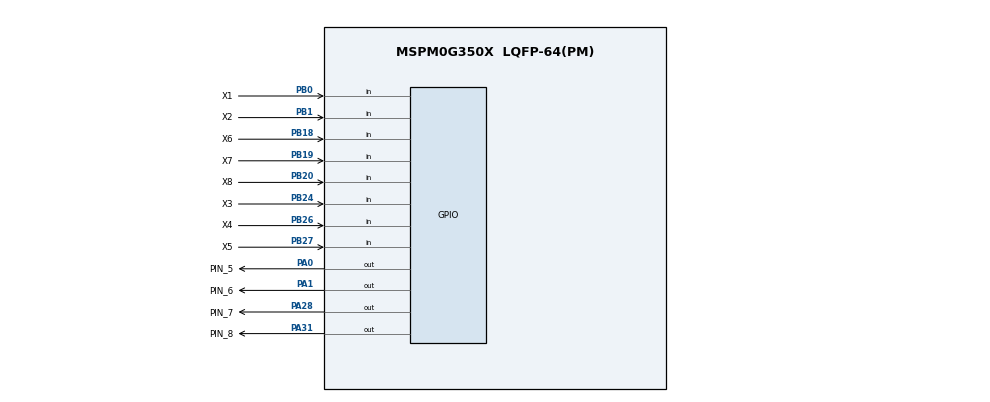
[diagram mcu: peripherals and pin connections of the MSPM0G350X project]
/**
 * @cliArgs --device "MSPM0G350X" --part "Default" --package "LQFP-64(PM)" --product "mspm0_sdk@2.10.00.04"
 * @versions {"tool":"1.26.2+4477"}
 */

/**
 * Import the modules used in this configuration.
 */
const GPIO   = scripting.addModule("/ti/driverlib/GPIO", {}, false);
const GPIO1  = GPIO.addInstance();
const GPIO2  = GPIO.addInstance();
const SYSCTL = scripting.addModule("/ti/driverlib/SYSCTL");

/**
 * Write custom configuration values to the imported modules.
 */
GPIO1.$name                              = "IR_SENSOR";
GPIO1.associatedPins.create(8);
GPIO1.associatedPins[0].$name            = "X1";
GPIO1.associatedPins[0].direction        = "INPUT";
GPIO1.associatedPins[0].internalResistor = "PULL_UP";
GPIO1.associatedPins[0].pin.$assign      = "PB0";
GPIO1.associatedPins[1].$name            = "X2";
GPIO1.associatedPins[1].direction        = "INPUT";
GPIO1.associatedPins[1].internalResistor = "PULL_UP";
GPIO1.associatedPins[1].pin.$assign      = "PB1";
GPIO1.associatedPins[2].$name            = "X3";
GPIO1.associatedPins[2].direction        = "INPUT";
GPIO1.associatedPins[2].internalResistor = "PULL_UP";
GPIO1.associatedPins[2].pin.$assign      = "PB24";
GPIO1.associatedPins[3].$name            = "X4";
GPIO1.associatedPins[3].direction        = "INPUT";
GPIO1.associatedPins[3].internalResistor = "PULL_UP";
GPIO1.associatedPins[3].pin.$assign      = "PB26";
GPIO1.associatedPins[4].$name            = "X5";
GPIO1.associatedPins[4].direction        = "INPUT";
GPIO1.associatedPins[4].internalResistor = "PULL_UP";
GPIO1.associatedPins[4].pin.$assign      = "PB27";
GPIO1.associatedPins[5].$name            = "X6";
GPIO1.associatedPins[5].direction        = "INPUT";
GPIO1.associatedPins[5].internalResistor = "PULL_UP";
GPIO1.associatedPins[5].pin.$assign      = "PB18";
GPIO1.associatedPins[6].$name            = "X7";
GPIO1.associatedPins[6].direction        = "INPUT";
GPIO1.associatedPins[6].internalResistor = "PULL_UP";
GPIO1.associatedPins[6].pin.$assign      = "PB19";
GPIO1.associatedPins[7].$name            = "X8";
GPIO1.associatedPins[7].direction        = "INPUT";
GPIO1.associatedPins[7].internalResistor = "PULL_UP";
GPIO1.associatedPins[7].pin.$assign      = "PB20";

const Board = scripting.addModule("/ti/driverlib/Board", {}, false);

GPIO2.$name                         = "GPIO_MOTOR_DIR";
GPIO2.port                          = "PORTA";
GPIO2.associatedPins.create(4);
GPIO2.associatedPins[0].$name       = "PIN_5";
GPIO2.associatedPins[0].pin.$assign = "PA0";
GPIO2.associatedPins[1].$name       = "PIN_6";
GPIO2.associatedPins[1].pin.$assign = "PA1";
GPIO2.associatedPins[2].$name       = "PIN_7";
GPIO2.associatedPins[2].pin.$assign = "PA28";
GPIO2.associatedPins[3].$name       = "PIN_8";
GPIO2.associatedPins[3].pin.$assign = "PA31";

SYSCTL.forceDefaultClkConfig = true;

/**
 * Pinmux solution for unlocked pins/peripherals. This ensures that minor changes to the automatic solver in a future
 * version of the tool will not impact the pinmux you originally saw.  These lines can be completely deleted in order to
 * re-solve from scratch.
 */
Board.peripheral.$suggestSolution          = "DEBUGSS";
Board.peripheral.swclkPin.$suggestSolution = "PA20";
Board.peripheral.swdioPin.$suggestSolution = "PA19";
SYSCTL.peripheral.$suggestSolution         = "SYSCTL";
